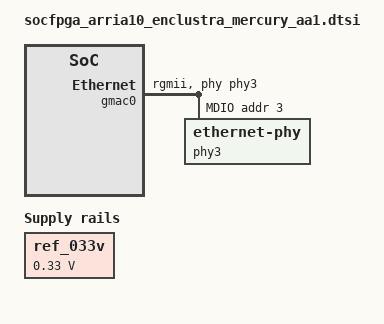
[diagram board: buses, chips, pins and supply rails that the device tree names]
/ {
	aliases {
		ethernet0 = &gmac0;
		serial0 = &uart1;
	};

	chosen {
		bootargs = "earlyprintk";
		stdout-path = "serial0:115200n8";
	};

	ref_033v: 033-v-ref {
		compatible = "regulator-fixed";
		regulator-name = "0.33V";
		regulator-min-microvolt = <330000>;
		regulator-max-microvolt = <330000>;
	};
};

&osc1 {
	clock-frequency = <33330000>;
};

&gmac0 {
	phy-mode = "rgmii";
	phy-addr = <0xffffffff>; /* probe for phy addr */

	/*
	 * These skews assume the user's FPGA design is adding 600ps of delay
	 * for TX_CLK on Arria 10.
	 *
	 * All skews are offset since hardware skew values for the ksz9031
	 * range from a negative skew to a positive skew.
	 * See the micrel-ksz90x1.txt Documentation file for details.
	 */
	txd0-skew-ps = <0>; /* -420ps */
	txd1-skew-ps = <0>; /* -420ps */
	txd2-skew-ps = <0>; /* -420ps */
	txd3-skew-ps = <0>; /* -420ps */
	rxd0-skew-ps = <420>; /* 0ps */
	rxd1-skew-ps = <420>; /* 0ps */
	rxd2-skew-ps = <420>; /* 0ps */
	rxd3-skew-ps = <420>; /* 0ps */
	txen-skew-ps = <0>; /* -420ps */
	txc-skew-ps = <1860>; /* 960ps */
	rxdv-skew-ps = <420>; /* 0ps */
	rxc-skew-ps = <1680>; /* 780ps */
	max-frame-size = <3800>;
	status = "okay";

	phy-handle = <&phy3>;

	mdio0 {
		#address-cells = <1>;
		#size-cells = <0>;
		compatible = "snps,dwmac-mdio";
		phy3: ethernet-phy@3 {
			reg = <3>;
		};
	};
};
